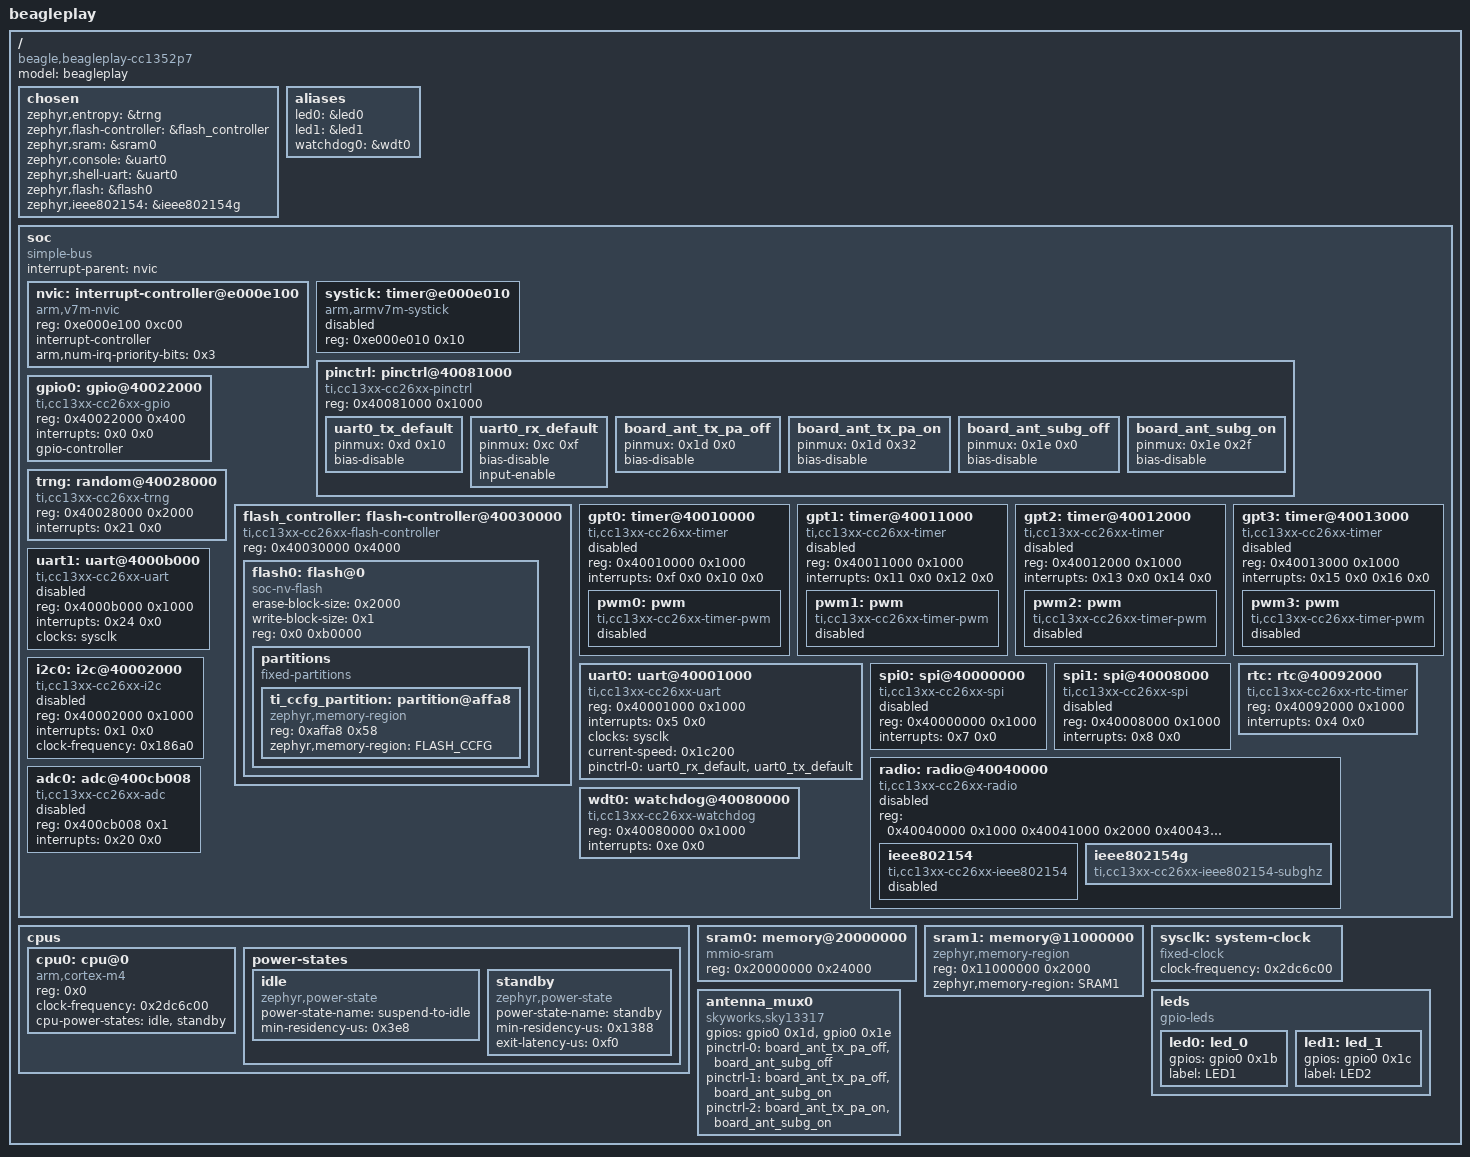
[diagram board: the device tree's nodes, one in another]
/dts-v1/;

/* node '/' defined in zephyr/dts/common/skeleton.dtsi:9 */
/ {
	#address-cells = < 0x1 >;                  /* in zephyr/dts/common/skeleton.dtsi:10 */
	#size-cells = < 0x1 >;                     /* in zephyr/dts/common/skeleton.dtsi:11 */
	model = "beagleplay";                      /* in zephyr/boards/beagle/beagleplay/beagleplay_cc1352p7.dts:13 */
	compatible = "beagle,beagleplay-cc1352p7"; /* in zephyr/boards/beagle/beagleplay/beagleplay_cc1352p7.dts:14 */

	/* node '/chosen' defined in zephyr/dts/common/skeleton.dtsi:13 */
	chosen {
		zephyr,entropy = &trng;                      /* in zephyr/dts/arm/ti/cc13xx_cc26xx.dtsi:15 */
		zephyr,flash-controller = &flash_controller; /* in zephyr/dts/arm/ti/cc13xx_cc26xx.dtsi:16 */
		zephyr,sram = &sram0;                        /* in zephyr/boards/beagle/beagleplay/beagleplay_cc1352p7.dts:23 */
		zephyr,console = &uart0;                     /* in zephyr/boards/beagle/beagleplay/beagleplay_cc1352p7.dts:24 */
		zephyr,shell-uart = &uart0;                  /* in zephyr/boards/beagle/beagleplay/beagleplay_cc1352p7.dts:25 */
		zephyr,flash = &flash0;                      /* in zephyr/boards/beagle/beagleplay/beagleplay_cc1352p7.dts:26 */
		zephyr,ieee802154 = &ieee802154g;            /* in zephyr/boards/beagle/beagleplay/beagleplay_cc1352p7.dts:27 */
	};

	/* node '/aliases' defined in zephyr/dts/common/skeleton.dtsi:15 */
	aliases {
		led0 = &led0;      /* in zephyr/boards/beagle/beagleplay/beagleplay_cc1352p7.dts:17 */
		led1 = &led1;      /* in zephyr/boards/beagle/beagleplay/beagleplay_cc1352p7.dts:18 */
		watchdog0 = &wdt0; /* in zephyr/boards/beagle/beagleplay/beagleplay_cc1352p7.dts:19 */
	};

	/* node '/soc' defined in zephyr/dts/arm/armv7-m.dtsi:6 */
	soc {
		#address-cells = < 0x1 >;     /* in zephyr/dts/arm/armv7-m.dtsi:7 */
		#size-cells = < 0x1 >;        /* in zephyr/dts/arm/armv7-m.dtsi:8 */
		compatible = "simple-bus";    /* in zephyr/dts/arm/armv7-m.dtsi:9 */
		interrupt-parent = < &nvic >; /* in zephyr/dts/arm/armv7-m.dtsi:10 */
		ranges;                       /* in zephyr/dts/arm/armv7-m.dtsi:11 */

		/* node '/soc/interrupt-controller@e000e100' defined in zephyr/dts/arm/armv7-m.dtsi:13 */
		nvic: interrupt-controller@e000e100 {
			#address-cells = < 0x1 >;            /* in zephyr/dts/arm/armv7-m.dtsi:14 */
			compatible = "arm,v7m-nvic";         /* in zephyr/dts/arm/armv7-m.dtsi:15 */
			reg = < 0xe000e100 0xc00 >;          /* in zephyr/dts/arm/armv7-m.dtsi:16 */
			interrupt-controller;                /* in zephyr/dts/arm/armv7-m.dtsi:17 */
			#interrupt-cells = < 0x2 >;          /* in zephyr/dts/arm/armv7-m.dtsi:18 */
			arm,num-irq-priority-bits = < 0x3 >; /* in zephyr/dts/arm/ti/cc13xx_cc26xx.dtsi:246 */
			phandle = < 0x1 >;                   /* in zephyr/dts/arm/armv7-m.dtsi:10 */
		};

		/* node '/soc/timer@e000e010' defined in zephyr/dts/arm/armv7-m.dtsi:21 */
		systick: timer@e000e010 {
			compatible = "arm,armv7m-systick"; /* in zephyr/dts/arm/armv7-m.dtsi:22 */
			reg = < 0xe000e010 0x10 >;         /* in zephyr/dts/arm/armv7-m.dtsi:23 */
			status = "disabled";               /* in zephyr/dts/arm/ti/cc13xx_cc26xx.dtsi:250 */
		};

		/* node '/soc/pinctrl@40081000' defined in zephyr/dts/arm/ti/cc13xx_cc26xx.dtsi:64 */
		pinctrl: pinctrl@40081000 {
			compatible = "ti,cc13xx-cc26xx-pinctrl"; /* in zephyr/dts/arm/ti/cc13xx_cc26xx.dtsi:65 */
			reg = < 0x40081000 0x1000 >;             /* in zephyr/dts/arm/ti/cc13xx_cc26xx.dtsi:66 */

			/* node '/soc/pinctrl@40081000/uart0_tx_default' defined in zephyr/boards/beagle/beagleplay/beagleplay-cc1352p7-pinctrl.dtsi:11 */
			uart0_tx_default: uart0_tx_default {
				pinmux = < 0xd 0x10 >; /* in zephyr/boards/beagle/beagleplay/beagleplay-cc1352p7-pinctrl.dtsi:12 */
				bias-disable;          /* in zephyr/boards/beagle/beagleplay/beagleplay-cc1352p7-pinctrl.dtsi:13 */
				phandle = < 0x4 >;     /* in zephyr/boards/beagle/beagleplay/beagleplay_cc1352p7.dts:83 */
			};

			/* node '/soc/pinctrl@40081000/uart0_rx_default' defined in zephyr/boards/beagle/beagleplay/beagleplay-cc1352p7-pinctrl.dtsi:16 */
			uart0_rx_default: uart0_rx_default {
				pinmux = < 0xc 0xf >; /* in zephyr/boards/beagle/beagleplay/beagleplay-cc1352p7-pinctrl.dtsi:17 */
				bias-disable;         /* in zephyr/boards/beagle/beagleplay/beagleplay-cc1352p7-pinctrl.dtsi:18 */
				input-enable;         /* in zephyr/boards/beagle/beagleplay/beagleplay-cc1352p7-pinctrl.dtsi:19 */
				phandle = < 0x3 >;    /* in zephyr/boards/beagle/beagleplay/beagleplay_cc1352p7.dts:83 */
			};

			/* node '/soc/pinctrl@40081000/board_ant_tx_pa_off' defined in zephyr/boards/beagle/beagleplay/beagleplay-cc1352p7-pinctrl.dtsi:23 */
			board_ant_tx_pa_off: board_ant_tx_pa_off {
				pinmux = < 0x1d 0x0 >; /* in zephyr/boards/beagle/beagleplay/beagleplay-cc1352p7-pinctrl.dtsi:24 */
				bias-disable;          /* in zephyr/boards/beagle/beagleplay/beagleplay-cc1352p7-pinctrl.dtsi:25 */
				phandle = < 0x8 >;     /* in zephyr/boards/beagle/beagleplay/beagleplay_cc1352p7.dts:60 */
			};

			/* node '/soc/pinctrl@40081000/board_ant_tx_pa_on' defined in zephyr/boards/beagle/beagleplay/beagleplay-cc1352p7-pinctrl.dtsi:28 */
			board_ant_tx_pa_on: board_ant_tx_pa_on {
				pinmux = < 0x1d 0x32 >; /* in zephyr/boards/beagle/beagleplay/beagleplay-cc1352p7-pinctrl.dtsi:29 */
				bias-disable;           /* in zephyr/boards/beagle/beagleplay/beagleplay-cc1352p7-pinctrl.dtsi:30 */
				phandle = < 0xb >;      /* in zephyr/boards/beagle/beagleplay/beagleplay_cc1352p7.dts:62 */
			};

			/* node '/soc/pinctrl@40081000/board_ant_subg_off' defined in zephyr/boards/beagle/beagleplay/beagleplay-cc1352p7-pinctrl.dtsi:33 */
			board_ant_subg_off: board_ant_subg_off {
				pinmux = < 0x1e 0x0 >; /* in zephyr/boards/beagle/beagleplay/beagleplay-cc1352p7-pinctrl.dtsi:34 */
				bias-disable;          /* in zephyr/boards/beagle/beagleplay/beagleplay-cc1352p7-pinctrl.dtsi:35 */
				phandle = < 0x9 >;     /* in zephyr/boards/beagle/beagleplay/beagleplay_cc1352p7.dts:60 */
			};

			/* node '/soc/pinctrl@40081000/board_ant_subg_on' defined in zephyr/boards/beagle/beagleplay/beagleplay-cc1352p7-pinctrl.dtsi:38 */
			board_ant_subg_on: board_ant_subg_on {
				pinmux = < 0x1e 0x2f >; /* in zephyr/boards/beagle/beagleplay/beagleplay-cc1352p7-pinctrl.dtsi:39 */
				bias-disable;           /* in zephyr/boards/beagle/beagleplay/beagleplay-cc1352p7-pinctrl.dtsi:40 */
				phandle = < 0xa >;      /* in zephyr/boards/beagle/beagleplay/beagleplay_cc1352p7.dts:61 */
			};
		};

		/* node '/soc/gpio@40022000' defined in zephyr/dts/arm/ti/cc13xx_cc26xx.dtsi:69 */
		gpio0: gpio@40022000 {
			compatible = "ti,cc13xx-cc26xx-gpio"; /* in zephyr/dts/arm/ti/cc13xx_cc26xx.dtsi:70 */
			reg = < 0x40022000 0x400 >;           /* in zephyr/dts/arm/ti/cc13xx_cc26xx.dtsi:71 */
			interrupts = < 0x0 0x0 >;             /* in zephyr/dts/arm/ti/cc13xx_cc26xx.dtsi:72 */
			gpio-controller;                      /* in zephyr/dts/arm/ti/cc13xx_cc26xx.dtsi:74 */
			#gpio-cells = < 0x2 >;                /* in zephyr/dts/arm/ti/cc13xx_cc26xx.dtsi:75 */
			status = "okay";                      /* in zephyr/boards/beagle/beagleplay/beagleplay_cc1352p7.dts:77 */
			phandle = < 0x7 >;                    /* in zephyr/boards/beagle/beagleplay/beagleplay_cc1352p7.dts:34 */
		};

		/* node '/soc/random@40028000' defined in zephyr/dts/arm/ti/cc13xx_cc26xx.dtsi:78 */
		trng: random@40028000 {
			compatible = "ti,cc13xx-cc26xx-trng"; /* in zephyr/dts/arm/ti/cc13xx_cc26xx.dtsi:79 */
			reg = < 0x40028000 0x2000 >;          /* in zephyr/dts/arm/ti/cc13xx_cc26xx.dtsi:80 */
			interrupts = < 0x21 0x0 >;            /* in zephyr/dts/arm/ti/cc13xx_cc26xx.dtsi:81 */
			status = "okay";                      /* in zephyr/boards/beagle/beagleplay/beagleplay_cc1352p7.dts:73 */
		};

		/* node '/soc/flash-controller@40030000' defined in zephyr/dts/arm/ti/cc13xx_cc26xx.dtsi:85 */
		flash_controller: flash-controller@40030000 {
			compatible = "ti,cc13xx-cc26xx-flash-controller"; /* in zephyr/dts/arm/ti/cc13xx_cc26xx.dtsi:86 */
			reg = < 0x40030000 0x4000 >;                      /* in zephyr/dts/arm/ti/cc13xx_cc26xx.dtsi:87 */
			#address-cells = < 0x1 >;                         /* in zephyr/dts/arm/ti/cc13xx_cc26xx.dtsi:89 */
			#size-cells = < 0x1 >;                            /* in zephyr/dts/arm/ti/cc13xx_cc26xx.dtsi:90 */

			/* node '/soc/flash-controller@40030000/flash@0' defined in zephyr/dts/arm/ti/cc13xx_cc26xx.dtsi:92 */
			flash0: flash@0 {
				compatible = "soc-nv-flash";   /* in zephyr/dts/arm/ti/cc13xx_cc26xx.dtsi:93 */
				erase-block-size = < 0x2000 >; /* in zephyr/dts/arm/ti/cc13xx_cc26xx.dtsi:94 */
				write-block-size = < 0x1 >;    /* in zephyr/dts/arm/ti/cc13xx_cc26xx.dtsi:95 */
				reg = < 0x0 0xb0000 >;         /* in zephyr/dts/arm/ti/cc1352r7.dtsi:17 */

				/* node '/soc/flash-controller@40030000/flash@0/partitions' defined in zephyr/dts/arm/ti/cc1352r7.dtsi:19 */
				partitions {
					compatible = "fixed-partitions"; /* in zephyr/dts/arm/ti/cc1352r7.dtsi:20 */
					#address-cells = < 0x1 >;        /* in zephyr/dts/arm/ti/cc1352r7.dtsi:21 */
					#size-cells = < 0x1 >;           /* in zephyr/dts/arm/ti/cc1352r7.dtsi:22 */

					/* node '/soc/flash-controller@40030000/flash@0/partitions/partition@affa8' defined in zephyr/dts/arm/ti/cc1352r7.dtsi:25 */
					ti_ccfg_partition: partition@affa8 {
						compatible = "zephyr,memory-region"; /* in zephyr/dts/arm/ti/cc1352r7.dtsi:26 */
						reg = < 0xaffa8 0x58 >;              /* in zephyr/dts/arm/ti/cc1352r7.dtsi:27 */
						zephyr,memory-region = "FLASH_CCFG"; /* in zephyr/dts/arm/ti/cc1352r7.dtsi:28 */
					};
				};
			};
		};

		/* node '/soc/timer@40010000' defined in zephyr/dts/arm/ti/cc13xx_cc26xx.dtsi:99 */
		gpt0: timer@40010000 {
			compatible = "ti,cc13xx-cc26xx-timer"; /* in zephyr/dts/arm/ti/cc13xx_cc26xx.dtsi:100 */
			reg = < 0x40010000 0x1000 >;           /* in zephyr/dts/arm/ti/cc13xx_cc26xx.dtsi:101 */
			interrupts = < 0xf 0x0 0x10 0x0 >;     /* in zephyr/dts/arm/ti/cc13xx_cc26xx.dtsi:102 */
			interrupt-names = "gpt0a",
			                  "gpt0b";             /* in zephyr/dts/arm/ti/cc13xx_cc26xx.dtsi:103 */
			status = "disabled";                   /* in zephyr/dts/arm/ti/cc13xx_cc26xx.dtsi:104 */

			/* node '/soc/timer@40010000/pwm' defined in zephyr/dts/arm/ti/cc13xx_cc26xx.dtsi:106 */
			pwm0: pwm {
				compatible = "ti,cc13xx-cc26xx-timer-pwm"; /* in zephyr/dts/arm/ti/cc13xx_cc26xx.dtsi:107 */
				#pwm-cells = < 0x3 >;                      /* in zephyr/dts/arm/ti/cc13xx_cc26xx.dtsi:108 */
				status = "disabled";                       /* in zephyr/dts/arm/ti/cc13xx_cc26xx.dtsi:109 */
			};
		};

		/* node '/soc/timer@40011000' defined in zephyr/dts/arm/ti/cc13xx_cc26xx.dtsi:113 */
		gpt1: timer@40011000 {
			compatible = "ti,cc13xx-cc26xx-timer"; /* in zephyr/dts/arm/ti/cc13xx_cc26xx.dtsi:114 */
			reg = < 0x40011000 0x1000 >;           /* in zephyr/dts/arm/ti/cc13xx_cc26xx.dtsi:115 */
			interrupts = < 0x11 0x0 0x12 0x0 >;    /* in zephyr/dts/arm/ti/cc13xx_cc26xx.dtsi:116 */
			interrupt-names = "gpt1a",
			                  "gpt1b";             /* in zephyr/dts/arm/ti/cc13xx_cc26xx.dtsi:117 */
			status = "disabled";                   /* in zephyr/dts/arm/ti/cc13xx_cc26xx.dtsi:118 */

			/* node '/soc/timer@40011000/pwm' defined in zephyr/dts/arm/ti/cc13xx_cc26xx.dtsi:120 */
			pwm1: pwm {
				compatible = "ti,cc13xx-cc26xx-timer-pwm"; /* in zephyr/dts/arm/ti/cc13xx_cc26xx.dtsi:121 */
				#pwm-cells = < 0x3 >;                      /* in zephyr/dts/arm/ti/cc13xx_cc26xx.dtsi:122 */
				status = "disabled";                       /* in zephyr/dts/arm/ti/cc13xx_cc26xx.dtsi:123 */
			};
		};

		/* node '/soc/timer@40012000' defined in zephyr/dts/arm/ti/cc13xx_cc26xx.dtsi:127 */
		gpt2: timer@40012000 {
			compatible = "ti,cc13xx-cc26xx-timer"; /* in zephyr/dts/arm/ti/cc13xx_cc26xx.dtsi:128 */
			reg = < 0x40012000 0x1000 >;           /* in zephyr/dts/arm/ti/cc13xx_cc26xx.dtsi:129 */
			interrupts = < 0x13 0x0 0x14 0x0 >;    /* in zephyr/dts/arm/ti/cc13xx_cc26xx.dtsi:130 */
			interrupt-names = "gpt2a",
			                  "gpt2b";             /* in zephyr/dts/arm/ti/cc13xx_cc26xx.dtsi:131 */
			status = "disabled";                   /* in zephyr/dts/arm/ti/cc13xx_cc26xx.dtsi:132 */

			/* node '/soc/timer@40012000/pwm' defined in zephyr/dts/arm/ti/cc13xx_cc26xx.dtsi:134 */
			pwm2: pwm {
				compatible = "ti,cc13xx-cc26xx-timer-pwm"; /* in zephyr/dts/arm/ti/cc13xx_cc26xx.dtsi:135 */
				#pwm-cells = < 0x3 >;                      /* in zephyr/dts/arm/ti/cc13xx_cc26xx.dtsi:136 */
				status = "disabled";                       /* in zephyr/dts/arm/ti/cc13xx_cc26xx.dtsi:137 */
			};
		};

		/* node '/soc/timer@40013000' defined in zephyr/dts/arm/ti/cc13xx_cc26xx.dtsi:141 */
		gpt3: timer@40013000 {
			compatible = "ti,cc13xx-cc26xx-timer"; /* in zephyr/dts/arm/ti/cc13xx_cc26xx.dtsi:142 */
			reg = < 0x40013000 0x1000 >;           /* in zephyr/dts/arm/ti/cc13xx_cc26xx.dtsi:143 */
			interrupts = < 0x15 0x0 0x16 0x0 >;    /* in zephyr/dts/arm/ti/cc13xx_cc26xx.dtsi:144 */
			interrupt-names = "gpt3a",
			                  "gpt3b";             /* in zephyr/dts/arm/ti/cc13xx_cc26xx.dtsi:145 */
			status = "disabled";                   /* in zephyr/dts/arm/ti/cc13xx_cc26xx.dtsi:146 */

			/* node '/soc/timer@40013000/pwm' defined in zephyr/dts/arm/ti/cc13xx_cc26xx.dtsi:148 */
			pwm3: pwm {
				compatible = "ti,cc13xx-cc26xx-timer-pwm"; /* in zephyr/dts/arm/ti/cc13xx_cc26xx.dtsi:149 */
				#pwm-cells = < 0x3 >;                      /* in zephyr/dts/arm/ti/cc13xx_cc26xx.dtsi:150 */
				status = "disabled";                       /* in zephyr/dts/arm/ti/cc13xx_cc26xx.dtsi:151 */
			};
		};

		/* node '/soc/uart@40001000' defined in zephyr/dts/arm/ti/cc13xx_cc26xx.dtsi:155 */
		uart0: uart@40001000 {
			compatible = "ti,cc13xx-cc26xx-uart";                /* in zephyr/dts/arm/ti/cc13xx_cc26xx.dtsi:156 */
			reg = < 0x40001000 0x1000 >;                         /* in zephyr/dts/arm/ti/cc13xx_cc26xx.dtsi:157 */
			interrupts = < 0x5 0x0 >;                            /* in zephyr/dts/arm/ti/cc13xx_cc26xx.dtsi:158 */
			clocks = < &sysclk >;                                /* in zephyr/dts/arm/ti/cc13xx_cc26xx.dtsi:159 */
			status = "okay";                                     /* in zephyr/boards/beagle/beagleplay/beagleplay_cc1352p7.dts:81 */
			current-speed = < 0x1c200 >;                         /* in zephyr/boards/beagle/beagleplay/beagleplay_cc1352p7.dts:82 */
			pinctrl-0 = < &uart0_rx_default &uart0_tx_default >; /* in zephyr/boards/beagle/beagleplay/beagleplay_cc1352p7.dts:83 */
			pinctrl-names = "default";                           /* in zephyr/boards/beagle/beagleplay/beagleplay_cc1352p7.dts:84 */
		};

		/* node '/soc/uart@4000b000' defined in zephyr/dts/arm/ti/cc13xx_cc26xx.dtsi:163 */
		uart1: uart@4000b000 {
			compatible = "ti,cc13xx-cc26xx-uart"; /* in zephyr/dts/arm/ti/cc13xx_cc26xx.dtsi:164 */
			reg = < 0x4000b000 0x1000 >;          /* in zephyr/dts/arm/ti/cc13xx_cc26xx.dtsi:165 */
			interrupts = < 0x24 0x0 >;            /* in zephyr/dts/arm/ti/cc13xx_cc26xx.dtsi:166 */
			clocks = < &sysclk >;                 /* in zephyr/dts/arm/ti/cc13xx_cc26xx.dtsi:167 */
			status = "disabled";                  /* in zephyr/dts/arm/ti/cc13xx_cc26xx.dtsi:168 */
		};

		/* node '/soc/i2c@40002000' defined in zephyr/dts/arm/ti/cc13xx_cc26xx.dtsi:171 */
		i2c0: i2c@40002000 {
			compatible = "ti,cc13xx-cc26xx-i2c"; /* in zephyr/dts/arm/ti/cc13xx_cc26xx.dtsi:172 */
			#address-cells = < 0x1 >;            /* in zephyr/dts/arm/ti/cc13xx_cc26xx.dtsi:173 */
			#size-cells = < 0x0 >;               /* in zephyr/dts/arm/ti/cc13xx_cc26xx.dtsi:174 */
			reg = < 0x40002000 0x1000 >;         /* in zephyr/dts/arm/ti/cc13xx_cc26xx.dtsi:175 */
			interrupts = < 0x1 0x0 >;            /* in zephyr/dts/arm/ti/cc13xx_cc26xx.dtsi:176 */
			clock-frequency = < 0x186a0 >;       /* in zephyr/dts/arm/ti/cc13xx_cc26xx.dtsi:177 */
			status = "disabled";                 /* in zephyr/dts/arm/ti/cc13xx_cc26xx.dtsi:178 */
		};

		/* node '/soc/spi@40000000' defined in zephyr/dts/arm/ti/cc13xx_cc26xx.dtsi:181 */
		spi0: spi@40000000 {
			compatible = "ti,cc13xx-cc26xx-spi"; /* in zephyr/dts/arm/ti/cc13xx_cc26xx.dtsi:182 */
			#address-cells = < 0x1 >;            /* in zephyr/dts/arm/ti/cc13xx_cc26xx.dtsi:183 */
			#size-cells = < 0x0 >;               /* in zephyr/dts/arm/ti/cc13xx_cc26xx.dtsi:184 */
			reg = < 0x40000000 0x1000 >;         /* in zephyr/dts/arm/ti/cc13xx_cc26xx.dtsi:185 */
			interrupts = < 0x7 0x0 >;            /* in zephyr/dts/arm/ti/cc13xx_cc26xx.dtsi:186 */
			status = "disabled";                 /* in zephyr/dts/arm/ti/cc13xx_cc26xx.dtsi:187 */
		};

		/* node '/soc/spi@40008000' defined in zephyr/dts/arm/ti/cc13xx_cc26xx.dtsi:190 */
		spi1: spi@40008000 {
			compatible = "ti,cc13xx-cc26xx-spi"; /* in zephyr/dts/arm/ti/cc13xx_cc26xx.dtsi:191 */
			#address-cells = < 0x1 >;            /* in zephyr/dts/arm/ti/cc13xx_cc26xx.dtsi:192 */
			#size-cells = < 0x0 >;               /* in zephyr/dts/arm/ti/cc13xx_cc26xx.dtsi:193 */
			reg = < 0x40008000 0x1000 >;         /* in zephyr/dts/arm/ti/cc13xx_cc26xx.dtsi:194 */
			interrupts = < 0x8 0x0 >;            /* in zephyr/dts/arm/ti/cc13xx_cc26xx.dtsi:195 */
			status = "disabled";                 /* in zephyr/dts/arm/ti/cc13xx_cc26xx.dtsi:196 */
		};

		/* node '/soc/rtc@40092000' defined in zephyr/dts/arm/ti/cc13xx_cc26xx.dtsi:200 */
		rtc: rtc@40092000 {
			compatible = "ti,cc13xx-cc26xx-rtc-timer"; /* in zephyr/dts/arm/ti/cc13xx_cc26xx.dtsi:201 */
			reg = < 0x40092000 0x1000 >;               /* in zephyr/dts/arm/ti/cc13xx_cc26xx.dtsi:202 */
			interrupts = < 0x4 0x0 >;                  /* in zephyr/dts/arm/ti/cc13xx_cc26xx.dtsi:203 */
			status = "okay";                           /* in zephyr/boards/beagle/beagleplay/beagleplay_cc1352p7.dts:88 */
		};

		/* node '/soc/radio@40040000' defined in zephyr/dts/arm/ti/cc13xx_cc26xx.dtsi:207 */
		radio: radio@40040000 {
			compatible = "ti,cc13xx-cc26xx-radio";                                             /* in zephyr/dts/arm/ti/cc13xx_cc26xx.dtsi:208 */
			status = "disabled";                                                               /* in zephyr/dts/arm/ti/cc13xx_cc26xx.dtsi:209 */
			reg = < 0x40040000 0x1000 0x40041000 0x2000 0x40043000 0x1000 0x40044000 0x1000 >; /* in zephyr/dts/arm/ti/cc13xx_cc26xx.dtsi:211 */
			reg-names = "RFC_PWR",
			            "RFC_DBELL",
			            "RFC_RAT",
			            "RFC_FSCA";                                                            /* in zephyr/dts/arm/ti/cc13xx_cc26xx.dtsi:215 */

			/* node '/soc/radio@40040000/ieee802154' defined in zephyr/dts/arm/ti/cc13xx_cc26xx.dtsi:217 */
			ieee802154: ieee802154 {
				compatible = "ti,cc13xx-cc26xx-ieee802154"; /* in zephyr/dts/arm/ti/cc13xx_cc26xx.dtsi:218 */
				status = "disabled";                        /* in zephyr/boards/beagle/beagleplay/beagleplay_cc1352p7.dts:92 */
			};

			/* node '/soc/radio@40040000/ieee802154g' defined in zephyr/dts/arm/ti/cc13xx_cc26xx.dtsi:222 */
			ieee802154g: ieee802154g {
				compatible = "ti,cc13xx-cc26xx-ieee802154-subghz"; /* in zephyr/dts/arm/ti/cc13xx_cc26xx.dtsi:223 */
				status = "okay";                                   /* in zephyr/boards/beagle/beagleplay/beagleplay_cc1352p7.dts:96 */
			};
		};

		/* node '/soc/watchdog@40080000' defined in zephyr/dts/arm/ti/cc13xx_cc26xx.dtsi:228 */
		wdt0: watchdog@40080000 {
			compatible = "ti,cc13xx-cc26xx-watchdog"; /* in zephyr/dts/arm/ti/cc13xx_cc26xx.dtsi:229 */
			reg = < 0x40080000 0x1000 >;              /* in zephyr/dts/arm/ti/cc13xx_cc26xx.dtsi:230 */
			interrupts = < 0xe 0x0 >;                 /* in zephyr/dts/arm/ti/cc13xx_cc26xx.dtsi:231 */
			status = "okay";                          /* in zephyr/boards/beagle/beagleplay/beagleplay_cc1352p7.dts:100 */
		};

		/* node '/soc/adc@400cb008' defined in zephyr/dts/arm/ti/cc13xx_cc26xx.dtsi:235 */
		adc0: adc@400cb008 {
			compatible = "ti,cc13xx-cc26xx-adc"; /* in zephyr/dts/arm/ti/cc13xx_cc26xx.dtsi:236 */
			reg = < 0x400cb008 0x1 >;            /* in zephyr/dts/arm/ti/cc13xx_cc26xx.dtsi:237 */
			interrupts = < 0x20 0x0 >;           /* in zephyr/dts/arm/ti/cc13xx_cc26xx.dtsi:238 */
			status = "disabled";                 /* in zephyr/dts/arm/ti/cc13xx_cc26xx.dtsi:239 */
			#io-channel-cells = < 0x1 >;         /* in zephyr/dts/arm/ti/cc13xx_cc26xx.dtsi:240 */
		};
	};

	/* node '/cpus' defined in zephyr/dts/arm/ti/cc13xx_cc26xx.dtsi:19 */
	cpus {
		#address-cells = < 0x1 >; /* in zephyr/dts/arm/ti/cc13xx_cc26xx.dtsi:20 */
		#size-cells = < 0x0 >;    /* in zephyr/dts/arm/ti/cc13xx_cc26xx.dtsi:21 */

		/* node '/cpus/cpu@0' defined in zephyr/dts/arm/ti/cc13xx_cc26xx.dtsi:23 */
		cpu0: cpu@0 {
			device_type = "cpu";                   /* in zephyr/dts/arm/ti/cc13xx_cc26xx.dtsi:24 */
			compatible = "arm,cortex-m4";          /* in zephyr/dts/arm/ti/cc13xx_cc26xx.dtsi:25 */
			reg = < 0x0 >;                         /* in zephyr/dts/arm/ti/cc13xx_cc26xx.dtsi:26 */
			clock-frequency = < 0x2dc6c00 >;       /* in zephyr/boards/beagle/beagleplay/beagleplay_cc1352p7.dts:68 */
			cpu-power-states = < &idle &standby >; /* in zephyr/boards/beagle/beagleplay/beagleplay_cc1352p7.dts:69 */
		};

		/* node '/cpus/power-states' defined in zephyr/dts/arm/ti/cc13xx_cc26xx.dtsi:30 */
		power-states {

			/* node '/cpus/power-states/idle' defined in zephyr/dts/arm/ti/cc13xx_cc26xx.dtsi:31 */
			idle: idle {
				compatible = "zephyr,power-state";    /* in zephyr/dts/arm/ti/cc13xx_cc26xx.dtsi:32 */
				power-state-name = "suspend-to-idle"; /* in zephyr/dts/arm/ti/cc13xx_cc26xx.dtsi:33 */
				min-residency-us = < 0x3e8 >;         /* in zephyr/dts/arm/ti/cc13xx_cc26xx.dtsi:34 */
				phandle = < 0x5 >;                    /* in zephyr/boards/beagle/beagleplay/beagleplay_cc1352p7.dts:69 */
			};

			/* node '/cpus/power-states/standby' defined in zephyr/dts/arm/ti/cc13xx_cc26xx.dtsi:37 */
			standby: standby {
				compatible = "zephyr,power-state"; /* in zephyr/dts/arm/ti/cc13xx_cc26xx.dtsi:38 */
				power-state-name = "standby";      /* in zephyr/dts/arm/ti/cc13xx_cc26xx.dtsi:39 */
				min-residency-us = < 0x1388 >;     /* in zephyr/dts/arm/ti/cc13xx_cc26xx.dtsi:40 */
				exit-latency-us = < 0xf0 >;        /* in zephyr/dts/arm/ti/cc13xx_cc26xx.dtsi:41 */
				phandle = < 0x6 >;                 /* in zephyr/boards/beagle/beagleplay/beagleplay_cc1352p7.dts:69 */
			};
		};
	};

	/* node '/memory@20000000' defined in zephyr/dts/arm/ti/cc13xx_cc26xx.dtsi:46 */
	sram0: memory@20000000 {
		compatible = "mmio-sram";     /* in zephyr/dts/arm/ti/cc13xx_cc26xx.dtsi:47 */
		reg = < 0x20000000 0x24000 >; /* in zephyr/dts/arm/ti/cc1352r7.dtsi:12 */
	};

	/* node '/memory@11000000' defined in zephyr/dts/arm/ti/cc13xx_cc26xx.dtsi:51 */
	sram1: memory@11000000 {
		compatible = "zephyr,memory-region",
		             "mmio-sram";            /* in zephyr/dts/arm/ti/cc13xx_cc26xx.dtsi:52 */
		reg = < 0x11000000 0x2000 >;         /* in zephyr/dts/arm/ti/cc13xx_cc26xx.dtsi:53 */
		zephyr,memory-region = "SRAM1";      /* in zephyr/dts/arm/ti/cc13xx_cc26xx.dtsi:54 */
	};

	/* node '/system-clock' defined in zephyr/dts/arm/ti/cc13xx_cc26xx.dtsi:57 */
	sysclk: system-clock {
		compatible = "fixed-clock";      /* in zephyr/dts/arm/ti/cc13xx_cc26xx.dtsi:58 */
		clock-frequency = < 0x2dc6c00 >; /* in zephyr/dts/arm/ti/cc13xx_cc26xx.dtsi:59 */
		#clock-cells = < 0x0 >;          /* in zephyr/dts/arm/ti/cc13xx_cc26xx.dtsi:60 */
		phandle = < 0x2 >;               /* in zephyr/dts/arm/ti/cc13xx_cc26xx.dtsi:159 */
	};

	/* node '/leds' defined in zephyr/boards/beagle/beagleplay/beagleplay_cc1352p7.dts:30 */
	leds: leds {
		compatible = "gpio-leds"; /* in zephyr/boards/beagle/beagleplay/beagleplay_cc1352p7.dts:31 */

		/* node '/leds/led_0' defined in zephyr/boards/beagle/beagleplay/beagleplay_cc1352p7.dts:33 */
		led0: led_0 {
			gpios = < &gpio0 0x1b 0x0 >; /* in zephyr/boards/beagle/beagleplay/beagleplay_cc1352p7.dts:34 */
			label = "LED1";              /* in zephyr/boards/beagle/beagleplay/beagleplay_cc1352p7.dts:35 */
		};

		/* node '/leds/led_1' defined in zephyr/boards/beagle/beagleplay/beagleplay_cc1352p7.dts:38 */
		led1: led_1 {
			gpios = < &gpio0 0x1c 0x0 >; /* in zephyr/boards/beagle/beagleplay/beagleplay_cc1352p7.dts:39 */
			label = "LED2";              /* in zephyr/boards/beagle/beagleplay/beagleplay_cc1352p7.dts:40 */
		};
	};

	/* node '/antenna_mux0' defined in zephyr/boards/beagle/beagleplay/beagleplay_cc1352p7.dts:56 */
	antenna_mux0: antenna_mux0 {
		compatible = "skyworks,sky13317";                         /* in zephyr/boards/beagle/beagleplay/beagleplay_cc1352p7.dts:57 */
		status = "okay";                                          /* in zephyr/boards/beagle/beagleplay/beagleplay_cc1352p7.dts:58 */
		gpios = < &gpio0 0x1d 0x0 >,
		        < &gpio0 0x1e 0x0 >;                              /* in zephyr/boards/beagle/beagleplay/beagleplay_cc1352p7.dts:59 */
		pinctrl-0 = < &board_ant_tx_pa_off &board_ant_subg_off >; /* in zephyr/boards/beagle/beagleplay/beagleplay_cc1352p7.dts:60 */
		pinctrl-1 = < &board_ant_tx_pa_off &board_ant_subg_on >;  /* in zephyr/boards/beagle/beagleplay/beagleplay_cc1352p7.dts:61 */
		pinctrl-2 = < &board_ant_tx_pa_on &board_ant_subg_on >;   /* in zephyr/boards/beagle/beagleplay/beagleplay_cc1352p7.dts:62 */
		pinctrl-names = "default",
		                "ant_subg",
		                "ant_subg_pa";                            /* in zephyr/boards/beagle/beagleplay/beagleplay_cc1352p7.dts:63 */
	};
};
